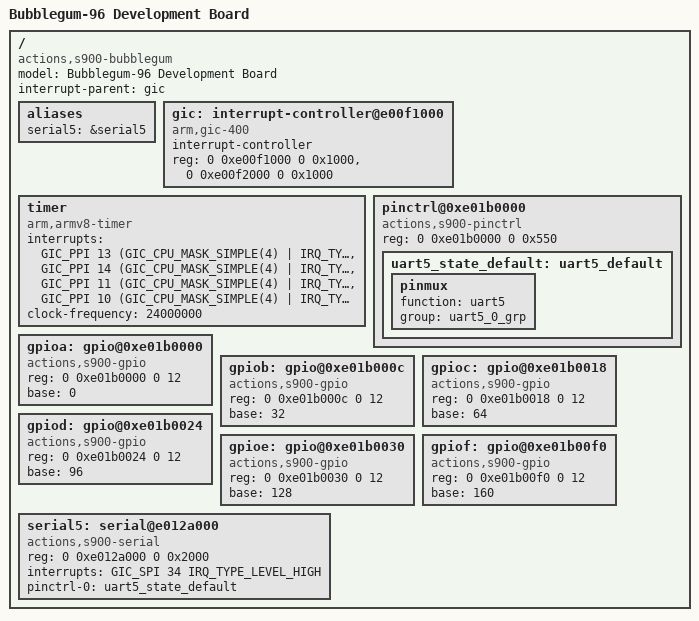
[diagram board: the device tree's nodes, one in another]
/*
 * dts file for Bubblegum-96 Development Board
 *
 * Copyright (C) 2016, wowotech.
 *
 */
/dts-v1/;

#include <dt-bindings/interrupt-controller/arm-gic.h>

/ {
	model = "Bubblegum-96 Development Board";
	compatible = "actions,s900-bubblegum", "actions,s900";

	interrupt-parent = <&gic>;

	#address-cells = <2>;
	#size-cells = <2>;

	aliases {
		serial5 = &serial5;
	};

	gic: interrupt-controller@e00f1000 {
		compatible = "arm,gic-400";
		#interrupt-cells = <3>;
		#address-cells = <0>;
		interrupt-controller;
		reg = <0 0xe00f1000 0 0x1000>,	/* dist_base */
		      <0 0xe00f2000 0 0x1000>;	/* cpu_base */
	};

	timer {
		compatible = "arm,armv8-timer";
		interrupts = <GIC_PPI 13 (GIC_CPU_MASK_SIMPLE(4) | IRQ_TYPE_LEVEL_LOW)>,
			     <GIC_PPI 14 (GIC_CPU_MASK_SIMPLE(4) | IRQ_TYPE_LEVEL_LOW)>,
			     <GIC_PPI 11 (GIC_CPU_MASK_SIMPLE(4) | IRQ_TYPE_LEVEL_LOW)>,
			     <GIC_PPI 10 (GIC_CPU_MASK_SIMPLE(4) | IRQ_TYPE_LEVEL_LOW)>;
		clock-frequency = <24000000>;
	};

	pinctrl@0xe01b0000 {
		compatible = "actions,s900-pinctrl";
		reg = <0 0xe01b0000 0 0x550>;

		uart5_state_default: uart5_default {
			pinmux {
				function = "uart5";
				group = "uart5_0_grp";
			};
			/* others, TODO */
		};
	};

	gpioa: gpio@0xe01b0000 {
		compatible = "actions,s900-gpio";
		reg = <0 0xe01b0000 0 12>;
		base = <0>;
	};
	gpiob: gpio@0xe01b000c {
		compatible = "actions,s900-gpio";
		reg = <0 0xe01b000c 0 12>;
		base = <32>;
	};
	gpioc: gpio@0xe01b0018 {
		compatible = "actions,s900-gpio";
		reg = <0 0xe01b0018 0 12>;
		base = <64>;
	};
	gpiod: gpio@0xe01b0024 {
		compatible = "actions,s900-gpio";
		reg = <0 0xe01b0024 0 12>;
		base = <96>;
	};
	gpioe: gpio@0xe01b0030 {
		compatible = "actions,s900-gpio";
		reg = <0 0xe01b0030 0 12>;
		base = <128>;
	};
	gpiof: gpio@0xe01b00f0 {
		compatible = "actions,s900-gpio";
		reg = <0 0xe01b00f0 0 12>;
		base = <160>;
	};

	serial5: serial@e012a000 {
		compatible = "actions,s900-serial";
		reg = <0 0xe012a000 0 0x2000>;	/* UART5_BASE */
		interrupts = <GIC_SPI 34 IRQ_TYPE_LEVEL_HIGH>;

		pinctrl-names = "default";
		pinctrl-0 = <&uart5_state_default>;
	};
};
